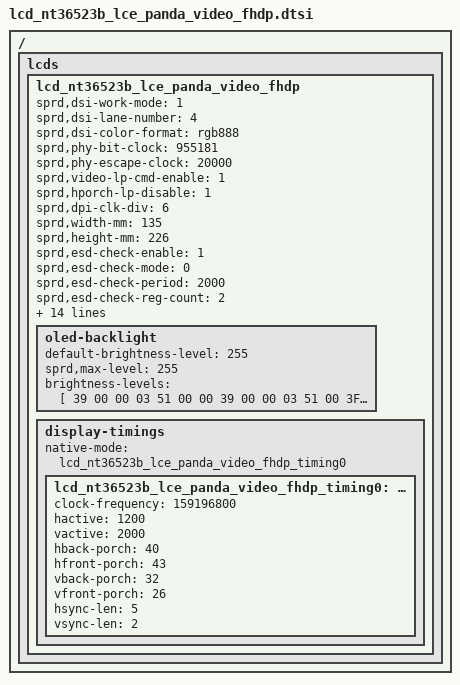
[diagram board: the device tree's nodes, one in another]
/ {
	fragment {
		target-path = "/";
		__overlay__ {
			lcds {
				lcd_nt36523b_lce_panda_video_fhdp: lcd_nt36523b_lce_panda_video_fhdp {

					sprd,dsi-work-mode = <1>; /* video burst mode*/
					sprd,dsi-lane-number = <4>;
					sprd,dsi-color-format = "rgb888";

					sprd,phy-bit-clock = <955181>;  /* kbps */
					sprd,phy-escape-clock = <20000>;/* kHz */

					sprd,video-lp-cmd-enable = <1>;
					sprd,hporch-lp-disable = <1>;
					sprd,dpi-clk-div = <6>;

					sprd,width-mm = <135>;
					sprd,height-mm = <226>;

					sprd,esd-check-enable = <1>;
					sprd,esd-check-mode = <0>;
					sprd,esd-check-period = <2000>;
					sprd,esd-check-reg-count = <2>;
					sprd,esd-check-register = [AB 0A];
					sprd,esd-check-value-len = <2 1>;
					sprd,esd-check-value = [00 00 9C];


					sprd,reset-on-sequence = <1 10>, <0 10>, <1 10>, <0 10>, <1 10>;
					sprd,reset-off-sequence = <1 1>;

					sprd,initial-command = [
						39 00 00 02 FF 20
						39 00 00 02 FB 01
						39 00 00 02 05 B1
						39 00 00 02 06 C0
						39 00 00 02 07 73
						39 00 00 02 08 4B
						39 00 00 02 0D 23
						39 00 00 02 0E 89
						39 00 00 02 0F 69
						39 00 00 02 88 00
						39 00 00 02 94 00
						39 00 00 02 95 C3
						39 00 00 02 96 C3
						39 00 00 02 09 99
						39 00 00 02 0A 88
						39 00 00 02 0B 10
						39 00 00 02 0C 00
						39 00 00 02 10 0C
						39 00 00 02 33 11
						39 00 00 02 58 60
						39 00 00 02 60 88
						39 00 00 02 30 10
						39 00 00 02 31 02
						39 00 00 02 32 C2
						39 00 00 02 75 A2
						39 00 00 02 77 66
						39 00 00 02 FF 20
						39 00 00 02 FB 01
						39 00 00 11 B0 00 08 00 22 00 49 00 69 00 84 00 9B 00 AF 00 C2
						39 00 00 11 B1 00 D2 01 0B 01 33 01 74 01 A2 01 ED 02 24 02 26
						39 00 00 11 B2 02 5E 02 9B 02 CA 03 03 03 2D 03 5E 03 70 03 81
						39 00 00 0D B3 03 95 03 A8 03 BC 03 CC 03 D5 03 D6
						39 00 00 11 B4 00 08 00 22 00 49 00 69 00 84 00 9B 00 AF 00 C2
						39 00 00 11 B5 00 D2 01 0B 01 33 01 74 01 A2 01 ED 02 24 02 26
						39 00 00 11 B6 02 5E 02 9B 02 CA 03 03 03 2D 03 5E 03 70 03 81
						39 00 00 0D B7 03 95 03 A8 03 BC 03 CC 03 D5 03 D6
						39 00 00 11 B8 00 08 00 22 00 49 00 69 00 84 00 9B 00 AF 00 C2
						39 00 00 11 B9 00 D2 01 0B 01 33 01 74 01 A2 01 ED 02 24 02 26
						39 00 00 11 BA 02 5E 02 9B 02 CA 03 03 03 2D 03 5E 03 70 03 81
						39 00 00 0D BB 03 95 03 A8 03 BC 03 CC 03 D5 03 D6
						39 00 00 02 C6 00
						39 00 00 02 C7 00
						39 00 00 02 C8 00
						39 00 00 02 C9 00
						39 00 00 02 CA 00
						39 00 00 02 CB 00
						39 00 00 02 CC 00
						39 00 00 02 CD 00
						39 00 00 02 CE 00
						39 00 00 02 CF 00
						39 00 00 02 D0 00
						39 00 00 02 D1 00
						39 00 00 02 D2 00
						39 00 00 02 D3 00
						39 00 00 02 D4 00
						39 00 00 02 D5 00
						39 00 00 02 D6 00
						39 00 00 02 D7 00
						39 00 00 02 D8 00
						39 00 00 02 D9 00
						39 00 00 02 DA 00
						39 00 00 02 DB 00
						39 00 00 02 DC 00
						39 00 00 02 DD 00
						39 00 00 02 DE 00
						39 00 00 02 DF 00
						39 00 00 02 E0 00
						39 00 00 02 E1 00
						39 00 00 02 E2 00
						39 00 00 02 E3 00
						39 00 00 02 FF 21
						39 00 00 02 FB 01
						39 00 00 11 B0 00 00 00 1A 00 41 00 61 00 7C 00 93 00 A7 00 BA
						39 00 00 11 B1 00 CA 01 03 01 2B 01 6C 01 9A 01 E5 02 1C 02 1E
						39 00 00 11 B2 02 56 02 93 02 C2 02 FB 03 25 03 56 03 68 03 79
						39 00 00 0D B3 03 8D 03 A0 03 B4 03 C4 03 CD 03 CE
						39 00 00 11 B4 00 00 00 1A 00 41 00 61 00 7C 00 93 00 A7 00 BA
						39 00 00 11 B5 00 CA 01 03 01 2B 01 6C 01 9A 01 E5 02 1C 02 1E
						39 00 00 11 B6 02 56 02 93 02 C2 02 FB 03 25 03 56 03 68 03 79
						39 00 00 0D B7 03 8D 03 A0 03 B4 03 C4 03 CD 03 CE
						39 00 00 11 B8 00 00 00 1A 00 41 00 61 00 7C 00 93 00 A7 00 BA
						39 00 00 11 B9 00 CA 01 03 01 2B 01 6C 01 9A 01 E5 02 1C 02 1E
						39 00 00 11 BA 02 56 02 93 02 C2 02 FB 03 25 03 56 03 68 03 79
						39 00 00 0D BB 03 8D 03 A0 03 B4 03 C4 03 CD 03 CE
						39 00 00 02 FF 23
						39 00 00 02 FB 01
						39 00 00 02 00 80
						39 00 00 02 07 00
						39 00 00 02 08 01
						39 00 00 02 09 00
						39 00 00 02 11 01
						39 00 00 02 12 77
						39 00 00 02 15 07
						39 00 00 02 16 07
						39 00 00 02 FF 24
						39 00 00 02 FB 01
						39 00 00 02 60 96
						39 00 00 02 61 D0
						39 00 00 02 63 70
						39 00 00 02 91 00
						39 00 00 02 92 D4
						39 00 00 02 93 1A
						39 00 00 02 94 08
						39 00 00 02 C2 CA
						39 00 00 02 00 29
						39 00 00 02 01 08
						39 00 00 02 02 28
						39 00 00 02 03 03
						39 00 00 02 04 04
						39 00 00 02 05 13
						39 00 00 02 06 12
						39 00 00 02 07 11
						39 00 00 02 08 10
						39 00 00 02 09 0F
						39 00 00 02 0A 0E
						39 00 00 02 0B 0D
						39 00 00 02 0C 0C
						39 00 00 02 0D 27
						39 00 00 02 0E 03
						39 00 00 02 0F 03
						39 00 00 02 10 03
						39 00 00 02 11 03
						39 00 00 02 12 03
						39 00 00 02 13 03
						39 00 00 02 14 03
						39 00 00 02 15 03
						39 00 00 02 16 29
						39 00 00 02 17 08
						39 00 00 02 18 28
						39 00 00 02 19 03
						39 00 00 02 1A 04
						39 00 00 02 1B 13
						39 00 00 02 1C 12
						39 00 00 02 1D 11
						39 00 00 02 1E 10
						39 00 00 02 1F 0F
						39 00 00 02 20 0E
						39 00 00 02 21 0D
						39 00 00 02 22 0C
						39 00 00 02 23 27
						39 00 00 02 24 03
						39 00 00 02 25 03
						39 00 00 02 26 03
						39 00 00 02 27 03
						39 00 00 02 28 03
						39 00 00 02 29 03
						39 00 00 02 2A 03
						39 00 00 02 2B 03
						39 00 00 02 2F 06
						39 00 00 02 33 06
						39 00 00 02 37 44
						39 00 00 02 3A 02
						39 00 00 02 3B 98
						39 00 00 02 3D 81
						39 00 00 02 AB 44
						39 00 00 02 3F 5B
						39 00 00 02 43 5B
						39 00 00 02 47 44
						39 00 00 02 4A 02
						39 00 00 02 4B 68
						39 00 00 02 4C 01
						39 00 00 02 F7 44
						39 00 00 02 4D 21
						39 00 00 02 4E 43
						39 00 00 02 4F 65
						39 00 00 02 50 87
						39 00 00 02 51 78
						39 00 00 02 52 56
						39 00 00 02 53 34
						39 00 00 02 54 12
						39 00 00 03 55 85 05
						39 00 00 02 56 08
						39 00 00 02 58 10
						39 00 00 02 59 20
						39 00 00 02 5A A0
						39 00 00 02 5B 98
						39 00 00 02 5C 00
						39 00 00 02 5D 00
						39 00 00 03 5E 00 04
						39 00 00 02 5F 00
						39 00 00 02 98 80
						39 00 00 02 AA 03
						39 00 00 02 D7 55
						39 00 00 02 D8 55
						39 00 00 02 D9 23
						39 00 00 02 DA 05
						39 00 00 02 DB 72
						39 00 00 02 DC D0
						39 00 00 02 DD 55
						39 00 00 02 DE 27
						39 00 00 02 DF 02
						39 00 00 02 E0 D0
						39 00 00 02 E1 02
						39 00 00 02 E2 D0
						39 00 00 02 E3 02
						39 00 00 02 E4 D0
						39 00 00 02 E5 02
						39 00 00 02 E6 D0
						39 00 00 02 E7 00
						39 00 00 02 E8 00
						39 00 00 02 E9 02
						39 00 00 02 EA D0
						39 00 00 02 EB 02
						39 00 00 02 EE D0
						39 00 00 02 EF 02
						39 00 00 02 F0 D0
						39 00 00 0D B6 05 00 05 00 00 00 00 00 05 05 00 00
						39 00 00 02 FF 25
						39 00 00 02 FB 01
						39 00 00 02 05 00
						39 00 00 02 13 03
						39 00 00 02 14 12
						39 00 00 02 1E 00
						39 00 00 02 1F A0
						39 00 00 02 20 98
						39 00 00 02 25 00
						39 00 00 02 26 A0
						39 00 00 02 27 98
						39 00 00 02 3F 00
						39 00 00 02 40 03
						39 00 00 02 43 00
						39 00 00 02 48 A0
						39 00 00 02 49 98
						39 00 00 02 44 02
						39 00 00 02 45 98
						39 00 00 02 46 02
						39 00 00 02 47 98
						39 00 00 02 5D 02
						39 00 00 02 5E 98
						39 00 00 02 5F 02
						39 00 00 02 60 98
						39 00 00 02 61 A0
						39 00 00 02 62 98
						39 00 00 02 6B 40
						39 00 00 02 6C 0D
						39 00 00 02 6D 0D
						39 00 00 02 6E 0E
						39 00 00 02 6F 0E
						39 00 00 02 78 00
						39 00 00 02 79 DA
						39 00 00 02 7A 00
						39 00 00 02 7B 68
						39 00 00 02 86 01
						39 00 00 02 87 0A
						39 00 00 02 88 1A
						39 00 00 02 C0 0C
						39 00 00 02 FF 26
						39 00 00 02 FB 01
						39 00 00 02 00 A1
						39 00 00 02 04 28
						39 00 00 02 06 30
						39 00 00 02 0C 11
						39 00 00 02 0D 00
						39 00 00 02 0F 09
						39 00 00 02 11 12
						39 00 00 02 12 50
						39 00 00 02 13 6D
						39 00 00 02 14 93
						39 00 00 02 15 00
						39 00 00 02 16 90
						39 00 00 02 17 A0
						39 00 00 02 18 86
						39 00 00 02 19 11
						39 00 00 02 1A 00
						39 00 00 02 1B 0E
						39 00 00 02 1C DC
						39 00 00 02 22 00
						39 00 00 02 23 00
						39 00 00 02 2A 11
						39 00 00 02 2B 00
						39 00 00 02 1D 00
						39 00 00 02 1E D4
						39 00 00 02 1F D4
						39 00 00 02 20 00
						39 00 00 02 21 07
						39 00 00 02 2F 03
						39 00 00 02 30 D4
						39 00 00 02 33 78
						39 00 00 02 34 16
						39 00 00 02 35 11
						39 00 00 02 39 04
						39 00 00 02 3A D4
						39 00 00 02 3B 06
						39 00 00 02 3F 00
						39 00 00 02 40 C8
						39 00 00 02 41 C8
						39 00 00 02 42 C8
						39 00 00 02 43 01
						39 00 00 02 44 C8
						39 00 00 02 45 05
						39 00 00 02 46 C8
						39 00 00 02 47 00
						39 00 00 02 48 C8
						39 00 00 02 49 05
						39 00 00 02 4A C8
						39 00 00 02 4B 80
						39 00 00 02 8B 28
						39 00 00 02 8C 00
						39 00 00 02 8D 01
						39 00 00 02 8F 01
						39 00 00 02 91 00
						39 00 00 02 92 50
						39 00 00 02 93 00
						39 00 00 02 94 00
						39 00 00 02 95 00
						39 00 00 02 96 00
						39 00 00 02 97 A0
						39 00 00 02 98 86
						39 00 00 02 99 0F
						39 00 00 02 9A 9C
						39 00 00 02 9B 0E
						39 00 00 02 9C DC
						39 00 00 02 9D 0F
						39 00 00 02 9E 9C
						39 00 00 02 9F 00
						39 00 00 02 A0 00
						39 00 00 02 C8 04
						39 00 00 02 C9 12
						39 00 00 02 CA 4E
						39 00 00 02 CB 00
						39 00 00 02 A9 79
						39 00 00 02 AA 7F
						39 00 00 02 AB 85
						39 00 00 02 AC 8B
						39 00 00 02 AD 91
						39 00 00 02 AE 97
						39 00 00 02 AF 9D
						39 00 00 02 B0 A3
						39 00 00 02 B1 A9
						39 00 00 02 B2 AF
						39 00 00 02 B3 B5
						39 00 00 02 B4 BB
						39 00 00 02 B5 C1
						39 00 00 02 B6 C7
						39 00 00 02 B7 CD
						39 00 00 02 B8 D3
						39 00 00 02 B9 D9
						39 00 00 02 FF 27
						39 00 00 02 FB 01
						39 00 00 02 00 00
						39 00 00 02 C3 00
						39 00 00 02 58 00
						39 00 00 02 78 00
						39 00 00 02 FF 2A
						39 00 00 02 FB 01
						39 00 00 02 64 86
						39 00 00 02 67 86
						39 00 00 02 68 03
						39 00 00 02 6A 86
						39 00 00 02 82 86
						39 00 00 02 85 86
						39 00 00 02 88 86
						39 00 00 02 89 03
						39 00 00 02 97 3C
						39 00 00 02 98 02
						39 00 00 02 99 95
						39 00 00 02 9A 06
						39 00 00 02 9B 00
						39 00 00 02 9C 0B
						39 00 00 02 9D 0A
						39 00 00 02 9E 90
						39 00 00 02 A2 3F
						39 00 00 02 A3 00
						39 00 00 02 A4 3C
						39 00 00 02 A5 03
						39 00 00 02 22 00
						39 00 00 02 23 08
						39 00 00 02 24 00
						39 00 00 02 25 D8
						39 00 00 02 26 F8
						39 00 00 02 27 00
						39 00 00 02 28 1A
						39 00 00 02 29 00
						39 00 00 02 2A 1A
						39 00 00 02 2B 00
						39 00 00 02 2D 1A
						39 00 00 02 E8 00
						39 00 00 02 FF D0
						39 00 00 02 FB 01
						39 00 00 02 02 7F
						39 00 00 02 09 EE
						39 00 00 02 FF F0
						39 00 00 02 FB 01
						39 00 00 02 3A 08
						39 00 00 02 FF 10
						39 00 00 02 B9 01
						39 00 00 02 FF 20
						39 00 00 02 FB 01
						39 00 00 02 18 40
						39 00 00 02 FF 10
						39 00 00 02 B9 02
						39 00 00 02 FF 25
						39 00 00 02 FB 01
						39 00 00 02 14 08
						39 00 00 02 19 07
						39 00 00 02 1B 11
						39 00 00 02 FF 10
						39 00 00 02 FB 01
						39 00 00 02 35 00
						39 00 00 02 BB 13
						39 00 00 06 3B 03 22 1A 04 04
						39 00 00 02 36 03	//old 00 Display flip 180 degrees 03
						39 00 00 02 53 2C
						39 00 00 03 68 02 01
						05 64 00 02 11 00
						05 14 00 02 29 00
						];

					sprd,sleep-in-command = [
						13 0A 00 01 28
						13 78 00 01 10
						];
					sprd,sleep-out-command = [
						13 78 00 01 11
						13 32 00 01 29
						];
					sprd,esd-master-command = [
						39 00 00 02 B9 02
						];
					sprd,esd-slave-command = [
						39 00 00 02 B9 03
						];

					oled-backlight {
						default-brightness-level = <255>;
						sprd,max-level = <255>;

						brightness-levels = [
							39 00 00 03 51 00 00
							39 00 00 03 51 00 3F
							39 00 00 03 51 00 3F
							39 00 00 03 51 00 3F
							39 00 00 03 51 00 4F
							39 00 00 03 51 00 5F
							39 00 00 03 51 00 6F
							39 00 00 03 51 00 7F
							39 00 00 03 51 00 8F
							39 00 00 03 51 00 9F
							39 00 00 03 51 00 AF
							39 00 00 03 51 00 BF
							39 00 00 03 51 00 CF
							39 00 00 03 51 00 DF
							39 00 00 03 51 00 EF
							39 00 00 03 51 00 FF
							39 00 00 03 51 01 0F
							39 00 00 03 51 01 1F
							39 00 00 03 51 01 2F
							39 00 00 03 51 01 3F
							39 00 00 03 51 01 4F
							39 00 00 03 51 01 5F
							39 00 00 03 51 01 6F
							39 00 00 03 51 01 7F
							39 00 00 03 51 01 8F
							39 00 00 03 51 01 9F
							39 00 00 03 51 01 AF
							39 00 00 03 51 01 BF
							39 00 00 03 51 01 CF
							39 00 00 03 51 01 DF
							39 00 00 03 51 01 EF
							39 00 00 03 51 01 FF
							39 00 00 03 51 02 0F
							39 00 00 03 51 02 1F
							39 00 00 03 51 02 2F
							39 00 00 03 51 02 3F
							39 00 00 03 51 02 4F
							39 00 00 03 51 02 5F
							39 00 00 03 51 02 6F
							39 00 00 03 51 02 7F
							39 00 00 03 51 02 8F
							39 00 00 03 51 02 9F
							39 00 00 03 51 02 AF
							39 00 00 03 51 02 BF
							39 00 00 03 51 02 CF
							39 00 00 03 51 02 DF
							39 00 00 03 51 02 EF
							39 00 00 03 51 02 FF
							39 00 00 03 51 03 0F
							39 00 00 03 51 03 1F
							39 00 00 03 51 03 2F
							39 00 00 03 51 03 3F
							39 00 00 03 51 03 4F
							39 00 00 03 51 03 5F
							39 00 00 03 51 03 6F
							39 00 00 03 51 03 7F
							39 00 00 03 51 03 8F
							39 00 00 03 51 03 9F
							39 00 00 03 51 03 AF
							39 00 00 03 51 03 BF
							39 00 00 03 51 03 CF
							39 00 00 03 51 03 DF
							39 00 00 03 51 03 EF
							39 00 00 03 51 03 FF
							39 00 00 03 51 04 0F
							39 00 00 03 51 04 1F
							39 00 00 03 51 04 2F
							39 00 00 03 51 04 3F
							39 00 00 03 51 04 4F
							39 00 00 03 51 04 5F
							39 00 00 03 51 04 6F
							39 00 00 03 51 04 7F
							39 00 00 03 51 04 8F
							39 00 00 03 51 04 9F
							39 00 00 03 51 04 AF
							39 00 00 03 51 04 BF
							39 00 00 03 51 04 CF
							39 00 00 03 51 04 DF
							39 00 00 03 51 04 EF
							39 00 00 03 51 04 FF
							39 00 00 03 51 05 0F
							39 00 00 03 51 05 1F
							39 00 00 03 51 05 2F
							39 00 00 03 51 05 3F
							39 00 00 03 51 05 4F
							39 00 00 03 51 05 5F
							39 00 00 03 51 05 6F
							39 00 00 03 51 05 7F
							39 00 00 03 51 05 8F
							39 00 00 03 51 05 9F
							39 00 00 03 51 05 AF
							39 00 00 03 51 05 BF
							39 00 00 03 51 05 CF
							39 00 00 03 51 05 DF
							39 00 00 03 51 05 EF
							39 00 00 03 51 05 FF
							39 00 00 03 51 06 0F
							39 00 00 03 51 06 1F
							39 00 00 03 51 06 2F
							39 00 00 03 51 06 3F
							39 00 00 03 51 06 4F
							39 00 00 03 51 06 5F
							39 00 00 03 51 06 6F
							39 00 00 03 51 06 7F
							39 00 00 03 51 06 8F
							39 00 00 03 51 06 9F
							39 00 00 03 51 06 AF
							39 00 00 03 51 06 BF
							39 00 00 03 51 06 CF
							39 00 00 03 51 06 DF
							39 00 00 03 51 06 EF
							39 00 00 03 51 06 FF
							39 00 00 03 51 07 0F
							39 00 00 03 51 07 1F
							39 00 00 03 51 07 2F
							39 00 00 03 51 07 3F
							39 00 00 03 51 07 4F
							39 00 00 03 51 07 5F
							39 00 00 03 51 07 6F
							39 00 00 03 51 07 7F
							39 00 00 03 51 07 8F
							39 00 00 03 51 07 9F
							39 00 00 03 51 07 AF
							39 00 00 03 51 07 BF
							39 00 00 03 51 07 CF
							39 00 00 03 51 07 DF
							39 00 00 03 51 07 EF
							39 00 00 03 51 07 FF
							39 00 00 03 51 08 0F
							39 00 00 03 51 08 1F
							39 00 00 03 51 08 2F
							39 00 00 03 51 08 3F
							39 00 00 03 51 08 4F
							39 00 00 03 51 08 5F
							39 00 00 03 51 08 6F
							39 00 00 03 51 08 7F
							39 00 00 03 51 08 8F
							39 00 00 03 51 08 9F
							39 00 00 03 51 08 AF
							39 00 00 03 51 08 BF
							39 00 00 03 51 08 CF
							39 00 00 03 51 08 DF
							39 00 00 03 51 08 EF
							39 00 00 03 51 08 FF
							39 00 00 03 51 09 0F
							39 00 00 03 51 09 1F
							39 00 00 03 51 09 2F
							39 00 00 03 51 09 3F
							39 00 00 03 51 09 4F
							39 00 00 03 51 09 5F
							39 00 00 03 51 09 6F
							39 00 00 03 51 09 7F
							39 00 00 03 51 09 8F
							39 00 00 03 51 09 9F
							39 00 00 03 51 09 AF
							39 00 00 03 51 09 BF
							39 00 00 03 51 09 CF
							39 00 00 03 51 09 DF
							39 00 00 03 51 09 EF
							39 00 00 03 51 09 FF
							39 00 00 03 51 0A 0F
							39 00 00 03 51 0A 1F
							39 00 00 03 51 0A 2F
							39 00 00 03 51 0A 3F
							39 00 00 03 51 0A 4F
							39 00 00 03 51 0A 5F
							39 00 00 03 51 0A 6F
							39 00 00 03 51 0A 7F
							39 00 00 03 51 0A 8F
							39 00 00 03 51 0A 9F
							39 00 00 03 51 0A AF
							39 00 00 03 51 0A BF
							39 00 00 03 51 0A CF
							39 00 00 03 51 0A DF
							39 00 00 03 51 0A EF
							39 00 00 03 51 0A FF
							39 00 00 03 51 0B 0F
							39 00 00 03 51 0B 1F
							39 00 00 03 51 0B 2F
							39 00 00 03 51 0B 3F
							39 00 00 03 51 0B 4F
							39 00 00 03 51 0B 5F
							39 00 00 03 51 0B 6F
							39 00 00 03 51 0B 7F
							39 00 00 03 51 0B 8F
							39 00 00 03 51 0B 9F
							39 00 00 03 51 0B AF
							39 00 00 03 51 0B BF
							39 00 00 03 51 0B CF
							39 00 00 03 51 0B DF
							39 00 00 03 51 0B EF
							39 00 00 03 51 0B FF
							39 00 00 03 51 0C 0F
							39 00 00 03 51 0C 1F
							39 00 00 03 51 0C 2F
							39 00 00 03 51 0C 3F
							39 00 00 03 51 0C 4F
							39 00 00 03 51 0C 5F
							39 00 00 03 51 0C 6F
							39 00 00 03 51 0C 7F
							39 00 00 03 51 0C 8F
							39 00 00 03 51 0C 9F
							39 00 00 03 51 0C AF
							39 00 00 03 51 0C BF
							39 00 00 03 51 0C CF
							39 00 00 03 51 0C DF
							39 00 00 03 51 0C EF
							39 00 00 03 51 0C FF
							39 00 00 03 51 0D 0F
							39 00 00 03 51 0D 1F
							39 00 00 03 51 0D 2F
							39 00 00 03 51 0D 3F
							39 00 00 03 51 0D 4F
							39 00 00 03 51 0D 5F
							39 00 00 03 51 0D 6F
							39 00 00 03 51 0D 7F
							39 00 00 03 51 0D 8F
							39 00 00 03 51 0D 9F
							39 00 00 03 51 0D AF
							39 00 00 03 51 0D BF
							39 00 00 03 51 0D CF
							39 00 00 03 51 0D DF
							39 00 00 03 51 0D EF
							39 00 00 03 51 0D FF
							39 00 00 03 51 0E 0F
							39 00 00 03 51 0E 1F
							39 00 00 03 51 0E 2F
							39 00 00 03 51 0E 3F
							39 00 00 03 51 0E 4F
							39 00 00 03 51 0E 5F
							39 00 00 03 51 0E 6F
							39 00 00 03 51 0E 7F
							39 00 00 03 51 0E 8F
							39 00 00 03 51 0E 9F
							39 00 00 03 51 0E AF
							39 00 00 03 51 0E BF
							39 00 00 03 51 0E CF
							39 00 00 03 51 0E DF
							39 00 00 03 51 0E EF
							39 00 00 03 51 0E FF
							39 00 00 03 51 0F 0F
							39 00 00 03 51 0F 1F
							39 00 00 03 51 0F 2F
							39 00 00 03 51 0F 3F
							39 00 00 03 51 0F 4F
							39 00 00 03 51 0F 5F
							39 00 00 03 51 0F 6F
							39 00 00 03 51 0F 7F
							39 00 00 03 51 0F 8F
							39 00 00 03 51 0F 9F
							39 00 00 03 51 0F AF
							39 00 00 03 51 0F BF
							39 00 00 03 51 0F CF
							39 00 00 03 51 0F DF
							39 00 00 03 51 0F EF
							39 00 00 03 51 0F FF
							];
						};

					display-timings {
						native-mode = <&lcd_nt36523b_lce_panda_video_fhdp_timing0>;

						lcd_nt36523b_lce_panda_video_fhdp_timing0: timing0 {
							clock-frequency = <159196800>;
							hactive = <1200>;
							vactive = <2000>;
							hback-porch = <40>;
							hfront-porch = <43>;
							vback-porch = <32>;
							vfront-porch = <26>;
							hsync-len = <5>;
							vsync-len = <2>;
						};
					};
				};
			};
		};
	};
};
